AUTOSAR XML (schema 4-0-3)
package /ComponentTypes
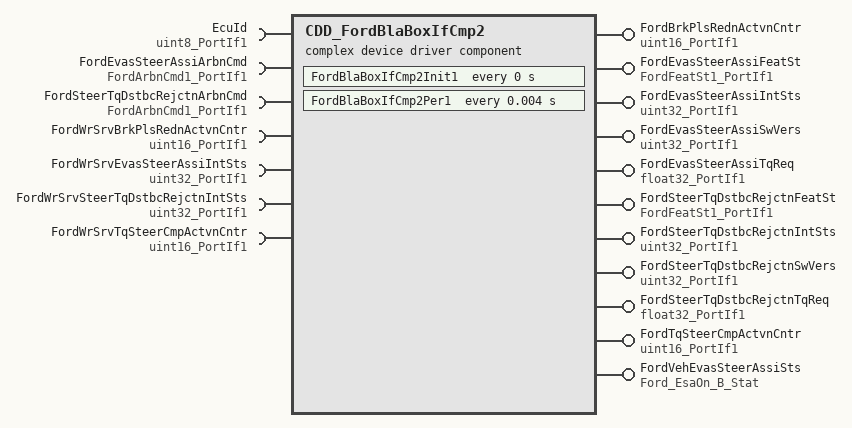
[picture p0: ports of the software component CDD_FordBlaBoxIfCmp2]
  complex device driver sw component type CDD_FordBlaBoxIfCmp2
    11 x provide port:
      FordBrkPlsRednActvnCntr: nonqueued-sender-com-spec{data-element=Val, init-value=0}, provided-interface=uint16_PortIf1
      FordEvasSteerAssiFeatSt: nonqueued-sender-com-spec{data-element=Val, init-value=0}, provided-interface=FordFeatSt1_PortIf1
      FordEvasSteerAssiIntSts: nonqueued-sender-com-spec{data-element=Val, init-value=0}, provided-interface=uint32_PortIf1
      FordEvasSteerAssiSwVers: nonqueued-sender-com-spec{data-element=Val, init-value=0}, provided-interface=uint32_PortIf1
      FordEvasSteerAssiTqReq: nonqueued-sender-com-spec=data-element=Val, provided-interface=float32_PortIf1
      FordSteerTqDstbcRejctnFeatSt: nonqueued-sender-com-spec{data-element=Val, init-value=0}, provided-interface=FordFeatSt1_PortIf1
      FordSteerTqDstbcRejctnIntSts: nonqueued-sender-com-spec{data-element=Val, init-value=0}, provided-interface=uint32_PortIf1
      FordSteerTqDstbcRejctnSwVers: nonqueued-sender-com-spec{data-element=Val, init-value=0}, provided-interface=uint32_PortIf1
      FordSteerTqDstbcRejctnTqReq: nonqueued-sender-com-spec{data-element=Val, init-value=0}, provided-interface=float32_PortIf1
      FordTqSteerCmpActvnCntr: nonqueued-sender-com-spec{data-element=Val, init-value=0}, provided-interface=uint16_PortIf1
      FordVehEvasSteerAssiSts: nonqueued-sender-com-spec=data-element=Ford_EsaOn_B_Stat, provided-interface=Ford_EsaOn_B_Stat
    7 x require port, all with nonqueued-receiver-com-spec{data-element=Val, filter=data-filter-type=ALWAYS, init-value=0}:
      EcuId: required-interface=uint8_PortIf1
      FordEvasSteerAssiArbnCmd: required-interface=FordArbnCmd1_PortIf1
      FordSteerTqDstbcRejctnArbnCmd: required-interface=FordArbnCmd1_PortIf1
      FordWrSrvBrkPlsRednActvnCntr: required-interface=uint16_PortIf1
      FordWrSrvEvasSteerAssiIntSts: required-interface=uint32_PortIf1
      FordWrSrvSteerTqDstbcRejctnIntSts: required-interface=uint32_PortIf1
      FordWrSrvTqSteerCmpActvnCntr: required-interface=uint16_PortIf1
    behavior CDD_FordBlaBoxIfCmp2_InternalBehavior
      ar-typed-per-instance-memorys:
        data EvasSteerAssiFctCallTog: sw-calibration-access=READ-ONLY, type=boolean
      timing event FordBlaBoxIfCmp2Init1_InitEvent: start-on-event=FordBlaBoxIfCmp2Init1, period=0
      timing event TMT_FordBlaBoxIfCmp2Per1: start-on-event=FordBlaBoxIfCmp2Per1, period=0.004
      port-api-options:
        enable-take-address=false, indirect-api=false, port=EcuId
        enable-take-address=false, indirect-api=false, port=FordBrkPlsRednActvnCntr
        enable-take-address=false, indirect-api=false, port=FordEvasSteerAssiArbnCmd
        enable-take-address=false, indirect-api=false, port=FordEvasSteerAssiFeatSt
        enable-take-address=false, indirect-api=false, port=FordEvasSteerAssiIntSts
        enable-take-address=false, indirect-api=false, port=FordEvasSteerAssiSwVers
        enable-take-address=false, indirect-api=false, port=FordEvasSteerAssiTqReq
        enable-take-address=false, indirect-api=false, port=FordSteerTqDstbcRejctnArbnCmd
        enable-take-address=false, indirect-api=false, port=FordSteerTqDstbcRejctnFeatSt
        enable-take-address=false, indirect-api=false, port=FordSteerTqDstbcRejctnIntSts
        enable-take-address=false, indirect-api=false, port=FordSteerTqDstbcRejctnSwVers
        enable-take-address=false, indirect-api=false, port=FordSteerTqDstbcRejctnTqReq
        enable-take-address=false, indirect-api=false, port=FordTqSteerCmpActvnCntr
        enable-take-address=false, indirect-api=false, port=FordVehEvasSteerAssiSts
        enable-take-address=false, indirect-api=false, port=FordWrSrvBrkPlsRednActvnCntr
        enable-take-address=false, indirect-api=false, port=FordWrSrvEvasSteerAssiIntSts
        enable-take-address=false, indirect-api=false, port=FordWrSrvSteerTqDstbcRejctnIntSts
        enable-take-address=false, indirect-api=false, port=FordWrSrvTqSteerCmpActvnCntr
      runnable FordBlaBoxIfCmp2Init1
        data-receive-point-by-arguments:
          7 x access:
            REC_EcuId_Val: accessed-variable=EcuId.Val
            REC_FordEvasSteerAssiArbnCmd_Val: accessed-variable=FordEvasSteerAssiArbnCmd.Val
            REC_FordSteerTqDstbcRejctnArbnCmd_Val: accessed-variable=FordSteerTqDstbcRejctnArbnCmd.Val
            REC_FordWrSrvBrkPlsRednActvnCntr_Val: accessed-variable=FordWrSrvBrkPlsRednActvnCntr.Val
            REC_FordWrSrvEvasSteerAssiIntSts_Val: accessed-variable=FordWrSrvEvasSteerAssiIntSts.Val
            REC_FordWrSrvSteerTqDstbcRejctnIntSts_Val: accessed-variable=FordWrSrvSteerTqDstbcRejctnIntSts.Val
            REC_FordWrSrvTqSteerCmpActvnCntr_Val: accessed-variable=FordWrSrvTqSteerCmpActvnCntr.Val
        data-send-points:
          11 x access:
            SEND_FordBrkPlsRednActvnCntr_Val: accessed-variable=FordBrkPlsRednActvnCntr.Val
            SEND_FordEvasSteerAssiFeatSt_Val_1: accessed-variable=FordEvasSteerAssiFeatSt.Val
            SEND_FordEvasSteerAssiIntSts_Val: accessed-variable=FordEvasSteerAssiIntSts.Val
            SEND_FordEvasSteerAssiSwVers_Val: accessed-variable=FordEvasSteerAssiSwVers.Val
            SEND_FordEvasSteerAssiTqReq_Val: accessed-variable=FordEvasSteerAssiTqReq.Val
            SEND_FordSteerTqDstbcRejctnFeatSt_Val_1: accessed-variable=FordSteerTqDstbcRejctnFeatSt.Val
            SEND_FordSteerTqDstbcRejctnIntSts_Val: accessed-variable=FordSteerTqDstbcRejctnIntSts.Val
            SEND_FordSteerTqDstbcRejctnSwVers_Val: accessed-variable=FordSteerTqDstbcRejctnSwVers.Val
            SEND_FordSteerTqDstbcRejctnTqReq_Val: accessed-variable=FordSteerTqDstbcRejctnTqReq.Val
            SEND_FordTqSteerCmpActvnCntr_Val: accessed-variable=FordTqSteerCmpActvnCntr.Val
            SEND_FordVehEvasSteerAssiSts_Ford_EsaOn_B_Stat: accessed-variable=FordVehEvasSteerAssiSts.Ford_EsaOn_B_Stat
      runnable FordBlaBoxIfCmp2Per1
        data-receive-point-by-arguments:
          7 x access:
            REC_EcuId_Val: accessed-variable=EcuId.Val
            REC_FordEvasSteerAssiArbnCmd_Val: accessed-variable=FordEvasSteerAssiArbnCmd.Val
            REC_FordSteerTqDstbcRejctnArbnCmd_Val: accessed-variable=FordSteerTqDstbcRejctnArbnCmd.Val
            REC_FordWrSrvBrkPlsRednActvnCntr_Val: accessed-variable=FordWrSrvBrkPlsRednActvnCntr.Val
            REC_FordWrSrvEvasSteerAssiIntSts_Val: accessed-variable=FordWrSrvEvasSteerAssiIntSts.Val
            REC_FordWrSrvSteerTqDstbcRejctnIntSts_Val: accessed-variable=FordWrSrvSteerTqDstbcRejctnIntSts.Val
            REC_FordWrSrvTqSteerCmpActvnCntr_Val: accessed-variable=FordWrSrvTqSteerCmpActvnCntr.Val
        data-send-points:
          11 x access:
            SEND_FordBrkPlsRednActvnCntr_Val: accessed-variable=FordBrkPlsRednActvnCntr.Val
            SEND_FordEvasSteerAssiFeatSt_Val_1: accessed-variable=FordEvasSteerAssiFeatSt.Val
            SEND_FordEvasSteerAssiIntSts_Val: accessed-variable=FordEvasSteerAssiIntSts.Val
            SEND_FordEvasSteerAssiSwVers_Val: accessed-variable=FordEvasSteerAssiSwVers.Val
            SEND_FordEvasSteerAssiTqReq_Val: accessed-variable=FordEvasSteerAssiTqReq.Val
            SEND_FordSteerTqDstbcRejctnFeatSt_Val_1: accessed-variable=FordSteerTqDstbcRejctnFeatSt.Val
            SEND_FordSteerTqDstbcRejctnIntSts_Val: accessed-variable=FordSteerTqDstbcRejctnIntSts.Val
            SEND_FordSteerTqDstbcRejctnSwVers_Val: accessed-variable=FordSteerTqDstbcRejctnSwVers.Val
            SEND_FordSteerTqDstbcRejctnTqReq_Val: accessed-variable=FordSteerTqDstbcRejctnTqReq.Val
            SEND_FordTqSteerCmpActvnCntr_Val: accessed-variable=FordTqSteerCmpActvnCntr.Val
            SEND_FordVehEvasSteerAssiSts_Ford_EsaOn_B_Stat: accessed-variable=FordVehEvasSteerAssiSts.Ford_EsaOn_B_Stat
  swc implementation CDD_FordBlaBoxIfCmp2_Implementation: behavior=CDD_FordBlaBoxIfCmp2_InternalBehavior
    code-descriptors:
      code Default: artifact-descriptors=autosar-engineering-object={short-label=Default, category=SWSRC}
